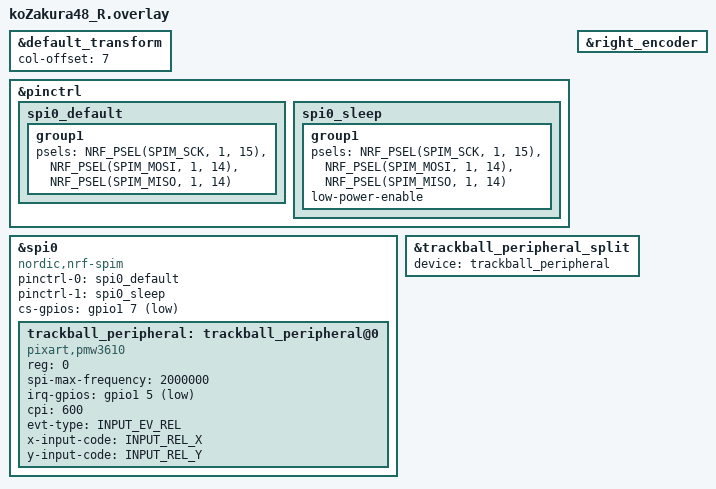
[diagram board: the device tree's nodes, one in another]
#include "koZakura48.dtsi"
#include <zephyr/dt-bindings/input/input-event-codes.h>

&default_transform {
    col-offset = <7>;
};

&pinctrl {
    spi0_default: spi0_default {
        group1 {
            psels = <NRF_PSEL(SPIM_SCK, 1, 15)>,
                <NRF_PSEL(SPIM_MOSI, 1, 14)>,
                <NRF_PSEL(SPIM_MISO, 1, 14)>;
        };
    };

    spi0_sleep: spi0_sleep {
        group1 {
            psels = <NRF_PSEL(SPIM_SCK, 1, 15)>,
                <NRF_PSEL(SPIM_MOSI, 1, 14)>,
                <NRF_PSEL(SPIM_MISO, 1, 14)>;
            low-power-enable;
        };
    };
};

&spi0 {
    status = "okay";
    compatible = "nordic,nrf-spim";
    pinctrl-0 = <&spi0_default>;
    pinctrl-1 = <&spi0_sleep>;
    pinctrl-names = "default", "sleep";
    cs-gpios = <&gpio1 7 GPIO_ACTIVE_LOW>;

    trackball_peripheral: trackball_peripheral@0 {
        status = "okay";
        compatible = "pixart,pmw3610";
        reg = <0>;
        spi-max-frequency = <2000000>;
        irq-gpios = <&gpio1 5 (GPIO_ACTIVE_LOW | GPIO_PULL_UP)>;
        cpi = <600>;
        evt-type = <INPUT_EV_REL>;
        x-input-code = <INPUT_REL_X>;
        y-input-code = <INPUT_REL_Y>;
    };
};

&right_encoder {
    status = "okay";
};

&trackball_peripheral_split {
    device = <&trackball_peripheral>;
};
